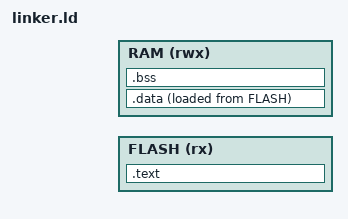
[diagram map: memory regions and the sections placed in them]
#include "mem_def.h"  /* generated by the tools/build.py */

ENTRY(_start)

MEMORY
{
    FLASH (rx)  : ORIGIN = FLASH_START, LENGTH = FLASH_SIZE
    RAM (rwx)   : ORIGIN = RAM_START, LENGTH = RAM_SIZE
}

SECTIONS
{
    .text : {
        _start = .;
        *(.text)
        *(.rodata)
        _etext = .;
    } > FLASH

    .data : {
        _sdata = .;
        *(.data)
        _edata = .;
    } > RAM AT > FLASH

    .bss : {
        _sbss = .;
        *(.bss)
        *(COMMON)
        _ebss = .;
    } > RAM
}
